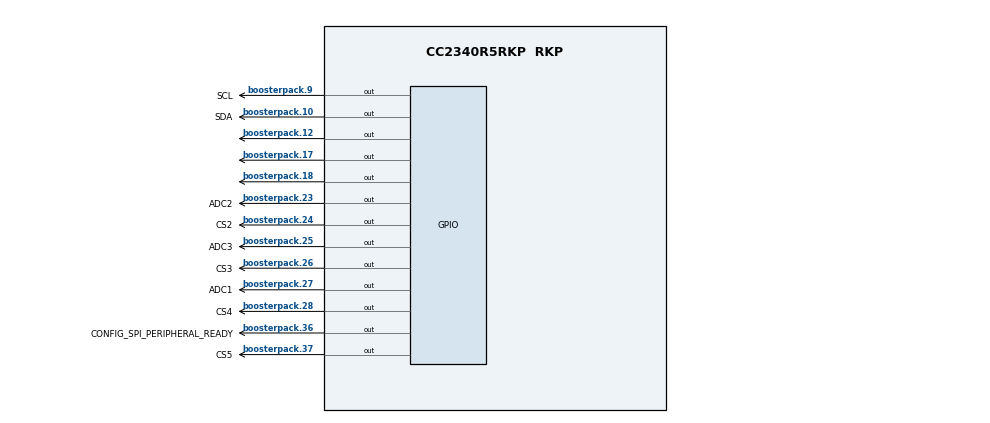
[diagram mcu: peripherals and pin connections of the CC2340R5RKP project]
/**
 * @cliArgs --board "/ti/boards/LP_EM_CC2340R5" --device "CC2340R5RKP" --part "Default" --package "RKP" --rtos "freertos" --product "simplelink_lowpower_f3_sdk@9.11.00.18"
 * @versions {"tool":"1.23.2+4156"}
 */

/**
 * Import the modules used in this configuration.
 */
const FreeRTOS = scripting.addModule("/freertos/FreeRTOS");
const Display  = scripting.addModule("/ti/display/Display");
const Display1 = Display.addInstance();
const GPIO     = scripting.addModule("/ti/drivers/GPIO");
const GPIO1    = GPIO.addInstance();
const GPIO2    = GPIO.addInstance();
const GPIO3    = GPIO.addInstance();
const GPIO4    = GPIO.addInstance();
const GPIO5    = GPIO.addInstance();
const GPIO6    = GPIO.addInstance();
const GPIO7    = GPIO.addInstance();
const GPIO8    = GPIO.addInstance();
const GPIO9    = GPIO.addInstance();
const GPIO10   = GPIO.addInstance();
const GPIO11   = GPIO.addInstance();
const GPIO12   = GPIO.addInstance();
const GPIO13   = GPIO.addInstance();
const GPIO14   = GPIO.addInstance();
const GPIO15   = GPIO.addInstance();
const GPIO16   = GPIO.addInstance();
const SPI      = scripting.addModule("/ti/drivers/SPI");
const SPI1     = SPI.addInstance();
const Settings = scripting.addModule("/ti/posix/freertos/Settings");

/**
 * Write custom configuration values to the imported modules.
 */
Display1.$name      = "CONFIG_Display_0";
Display1.$hardware  = system.deviceData.board.components.XDS110UART;
Display1.uart.$name = "CONFIG_UART2_0";

GPIO1.$hardware = system.deviceData.board.components.LED_RED;
GPIO1.$name     = "CONFIG_GPIO_LED_0";

GPIO2.$hardware = system.deviceData.board.components.LED_GREEN;
GPIO2.$name     = "CONFIG_GPIO_LED_1";

GPIO3.$name     = "CONFIG_SPI_CONTROLLER_READY";
GPIO3.$hardware = system.deviceData.board.components["BTN-1"];

GPIO4.$name           = "CONFIG_SPI_PERIPHERAL_READY";
GPIO4.gpioPin.$assign = "boosterpack.36";

GPIO5.$name           = "SCL";
GPIO5.gpioPin.$assign = "boosterpack.9";

GPIO6.$name           = "SDA";
GPIO6.gpioPin.$assign = "boosterpack.10";

GPIO7.$name           = "ADC1";
GPIO7.gpioPin.$assign = "boosterpack.27";

GPIO8.$name           = "ADC2";
GPIO8.gpioPin.$assign = "boosterpack.23";

GPIO9.$name           = "ADC3";
GPIO9.gpioPin.$assign = "boosterpack.25";

GPIO10.$name           = "CS2";
GPIO10.mode            = "Output";
GPIO10.gpioPin.$assign = "boosterpack.24";

GPIO11.$name           = "CS3";
GPIO11.mode            = "Output";
GPIO11.gpioPin.$assign = "boosterpack.26";

GPIO12.$name           = "CS4";
GPIO12.mode            = "Output";
GPIO12.gpioPin.$assign = "boosterpack.28";

GPIO13.$name           = "CS5";
GPIO13.mode            = "Output";
GPIO13.gpioPin.$assign = "boosterpack.37";

GPIO14.$name           = "CONFIG_GPIO_1";
GPIO14.gpioPin.$assign = "boosterpack.12";

GPIO15.$name           = "CONFIG_GPIO_2";
GPIO15.gpioPin.$assign = "boosterpack.17";

GPIO16.$name           = "CONFIG_GPIO_SPI_CONTROLLER_CSN";
GPIO16.mode            = "Output";
GPIO16.gpioPin.$assign = "boosterpack.18";

const CCFG              = scripting.addModule("/ti/devices/CCFG", {}, false);
CCFG.ccfgTemplate.$name = "ti_devices_CCFG_CCFGCC23X0Template0";

SPI1.$name                = "CONFIG_SPI_CONTROLLER";
SPI1.defaultTxBufferValue = "0xFF";
SPI1.$hardware            = system.deviceData.board.components.LP_SPI_BUS;

/**
 * Pinmux solution for unlocked pins/peripherals. This ensures that minor changes to the automatic solver in a future
 * version of the tool will not impact the pinmux you originally saw.  These lines can be completely deleted in order to
 * re-solve from scratch.
 */
Display1.uart.uart.$suggestSolution              = "UART0";
Display1.uart.uart.dmaTxChannel.$suggestSolution = "DMA_CH2";
Display1.uart.uart.dmaRxChannel.$suggestSolution = "DMA_CH3";
Display1.uart.uart.txPin.$suggestSolution        = "boosterpack.4";
Display1.uart.uart.rxPin.$suggestSolution        = "boosterpack.3";
GPIO1.gpioPin.$suggestSolution                   = "boosterpack.39";
GPIO2.gpioPin.$suggestSolution                   = "boosterpack.40";
GPIO3.gpioPin.$suggestSolution                   = "boosterpack.13";
SPI1.spi.$suggestSolution                        = "SPI0";
SPI1.spi.sclkPin.$suggestSolution                = "boosterpack.7";
SPI1.spi.dmaRxChannel.$suggestSolution           = "DMA_CH1";
SPI1.spi.dmaTxChannel.$suggestSolution           = "DMA_CH0";
SPI1.spi.pociPin.$suggestSolution                = "boosterpack.14";
SPI1.spi.picoPin.$suggestSolution                = "boosterpack.15";
